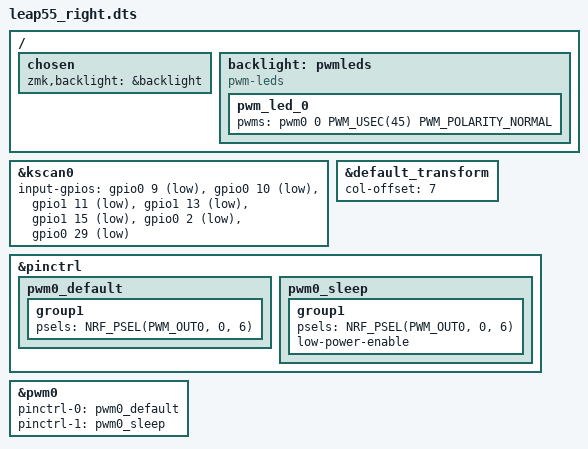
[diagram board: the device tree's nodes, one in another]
/*
 * Copyright (c) 2020 Pete Johanson
 *
 * SPDX-License-Identifier: MIT
 */

#include "leap55.dtsi" 

&kscan0 {
        input-gpios
            = <&gpio0 9 (GPIO_ACTIVE_LOW | GPIO_PULL_UP)>
            , <&gpio0 10  (GPIO_ACTIVE_LOW | GPIO_PULL_UP)>
            , <&gpio1 11  (GPIO_ACTIVE_LOW | GPIO_PULL_UP)>
            , <&gpio1 13  (GPIO_ACTIVE_LOW | GPIO_PULL_UP)>
            , <&gpio1 15 (GPIO_ACTIVE_LOW | GPIO_PULL_UP)>
            , <&gpio0 2  (GPIO_ACTIVE_LOW | GPIO_PULL_UP)>
            , <&gpio0 29  (GPIO_ACTIVE_LOW | GPIO_PULL_UP)>
           /* , <&gpio0 31 (GPIO_ACTIVE_LOW | GPIO_PULL_UP)>
            , <&gpio1 6  (GPIO_ACTIVE_LOW | GPIO_PULL_UP)>
            , <&gpio1 4  (GPIO_ACTIVE_LOW | GPIO_PULL_UP)>
            , <&gpio0 11  (GPIO_ACTIVE_LOW | GPIO_PULL_UP)>
            , <&gpio1 0  (GPIO_ACTIVE_LOW | GPIO_PULL_UP)>
            , <&gpio0 24  (GPIO_ACTIVE_LOW | GPIO_PULL_UP)>
            , <&gpio0 22  (GPIO_ACTIVE_LOW | GPIO_PULL_UP)>
            , <&gpio0 20  (GPIO_ACTIVE_LOW | GPIO_PULL_UP)>
            , <&gpio0 17  (GPIO_ACTIVE_LOW | GPIO_PULL_UP)>
            , <&gpio0 6  (GPIO_ACTIVE_LOW | GPIO_PULL_UP)>
            , <&gpio0 8  (GPIO_ACTIVE_LOW | GPIO_PULL_UP)> */        
            ;            
};   

&default_transform {
    col-offset = <7>;
};


&pinctrl {
    // Other pinctrl definitions for other hardware
    pwm0_default: pwm0_default {
        group1 {
            psels = <NRF_PSEL(PWM_OUT0, 0, 6)>;
        };
    };
    pwm0_sleep: pwm0_sleep {
        group1 {
            psels = <NRF_PSEL(PWM_OUT0, 0, 6)>;
            low-power-enable;
        };
    };
};


&pwm0 {
    status = "okay";
    pinctrl-0 = <&pwm0_default>;
    pinctrl-1 = <&pwm0_sleep>;
    pinctrl-names = "default", "sleep";
};


/ {
    chosen {
        zmk,backlight = &backlight;
    };
    backlight: pwmleds {
        compatible = "pwm-leds";
        pwm_led_0 {
            pwms = <&pwm0 0 PWM_USEC(45) PWM_POLARITY_NORMAL>;
        };
    };
};

